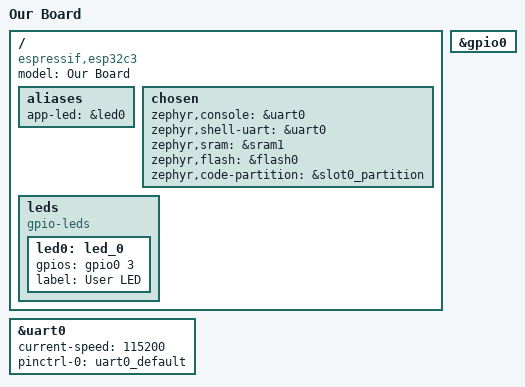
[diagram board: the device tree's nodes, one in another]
/dts-v1/;
#include <espressif/esp32c3/esp32c3_mini_n4.dtsi>
#include "esp32c3_devkitm-pinctrl.dtsi"
#include <espressif/partitions_0x0_default.dtsi>

/{
    model = "Our Board";
    compatible = "espressif,esp32c3";
    aliases {
        app-led = &led0;
    };

    chosen {
        zephyr,console = &uart0;
		zephyr,shell-uart = &uart0;
        zephyr,sram = &sram1;
		zephyr,flash = &flash0;
		zephyr,code-partition = &slot0_partition;
    };

    leds {
        compatible = "gpio-leds";
        led0: led_0  {
            gpios = <&gpio0 3 GPIO_ACTIVE_HIGH>;
            label = "User LED";
        };
    };
};
  &gpio0 {
	status = "okay";
};  
&uart0 {
	status = "okay";
	current-speed = <115200>;
	pinctrl-0 = <&uart0_default>;
	pinctrl-names = "default";
};
